# bao1x register map
Vendor: baochip; File version: 1.0
Registers are 32-bit, read-write, reset 0x0 unless marked. A register's access mark holds for its fields unless they carry their own. Offsets are from the block's base; [hi:lo] are bit positions; {n}, {i} and the like mark numbered series.

## IRQARRAY9
Base 0xE0017000
0x00 EV_SOFT — Software interrupt trigger register. ) Bits set to `1` will trigger an interrupt. Interrupts trigger on write, but the value will persist in the register, allowing software to determine if a software interrupt was triggered by reading back the register. Software is responsible for clearing the register to 0. Repeated `1` writes without clearing will still trigger an interrupt.
  [15:0] trigger
0x04 EV_EDGE_TRIGGERED — If a bit is set to 1, then the hardware trigger is edge-triggered
  [15:0] use_edge
0x08 EV_POLARITY — If a bit is set to 1, then the polarity is rising edge triggered; 0 is falling edge triggered. Bit is ignored if `edge_triggered` is 0.
  [15:0] rising
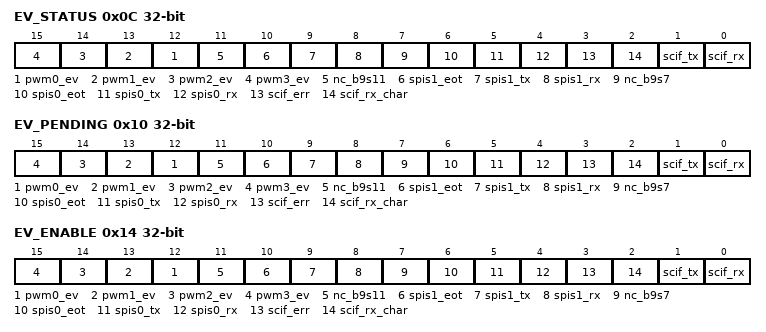
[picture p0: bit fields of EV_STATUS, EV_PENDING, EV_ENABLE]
0x0C EV_STATUS — `1` when a "pwm3_ev" event occurs. This event uses an `EventSourceFlex` form of triggering
  [n+12] pwm{n}_ev (n=0..3) — Level of the ``pwm{n}_ev`` event
  [11] nc_b9s11 — Level of the ``nc_b9s11`` event
  [10] spis1_eot — Level of the ``spis1_eot`` event
  [9] spis1_tx — Level of the ``spis1_tx`` event
  [8] spis1_rx — Level of the ``spis1_rx`` event
  [7] nc_b9s7 — Level of the ``nc_b9s7`` event
  [6] spis0_eot — Level of the ``spis0_eot`` event
  [5] spis0_tx — Level of the ``spis0_tx`` event
  [4] spis0_rx — Level of the ``spis0_rx`` event
  [3] scif_err — Level of the ``scif_err`` event
  [2] scif_rx_char — Level of the ``scif_rx_char`` event
  [1] scif_tx — Level of the ``scif_tx`` event
  [0] scif_rx — Level of the ``scif_rx`` event
0x10 EV_PENDING — `1` when a "pwm3_ev" event occurs. This event uses an `EventSourceFlex` form of triggering
  [n+12] pwm{n}_ev (n=0..3) — `1` when a "pwm{n}_ev" event occurs. This event uses an `EventSourceFlex` form of triggering
  [11] nc_b9s11 — `1` when a "nc_b9s11" event occurs. This event uses an `EventSourceFlex` form of triggering
  [10] spis1_eot — `1` when a "spis1_eot" event occurs. This event uses an `EventSourceFlex` form of triggering
  [9] spis1_tx — `1` when a "spis1_tx" event occurs. This event uses an `EventSourceFlex` form of triggering
  [8] spis1_rx — `1` when a "spis1_rx" event occurs. This event uses an `EventSourceFlex` form of triggering
  [7] nc_b9s7 — `1` when a "nc_b9s7" event occurs. This event uses an `EventSourceFlex` form of triggering
  [6] spis0_eot — `1` when a "spis0_eot" event occurs. This event uses an `EventSourceFlex` form of triggering
  [5] spis0_tx — `1` when a "spis0_tx" event occurs. This event uses an `EventSourceFlex` form of triggering
  [4] spis0_rx — `1` when a "spis0_rx" event occurs. This event uses an `EventSourceFlex` form of triggering
  [3] scif_err — `1` when a "scif_err" event occurs. This event uses an `EventSourceFlex` form of triggering
  [2] scif_rx_char — `1` when a "scif_rx_char" event occurs. This event uses an `EventSourceFlex` form of triggering
  [1] scif_tx — `1` when a "scif_tx" event occurs. This event uses an `EventSourceFlex` form of triggering
  [0] scif_rx — `1` when a "scif_rx" event occurs. This event uses an `EventSourceFlex` form of triggering
0x14 EV_ENABLE — `1` when a "pwm3_ev" event occurs. This event uses an `EventSourceFlex` form of triggering
  [n+12] pwm{n}_ev (n=0..3) — Write a ``1`` to enable the ``pwm{n}_ev`` Event
  [11] nc_b9s11 — Write a ``1`` to enable the ``nc_b9s11`` Event
  [10] spis1_eot — Write a ``1`` to enable the ``spis1_eot`` Event
  [9] spis1_tx — Write a ``1`` to enable the ``spis1_tx`` Event
  [8] spis1_rx — Write a ``1`` to enable the ``spis1_rx`` Event
  [7] nc_b9s7 — Write a ``1`` to enable the ``nc_b9s7`` Event
  [6] spis0_eot — Write a ``1`` to enable the ``spis0_eot`` Event
  [5] spis0_tx — Write a ``1`` to enable the ``spis0_tx`` Event
  [4] spis0_rx — Write a ``1`` to enable the ``spis0_rx`` Event
  [3] scif_err — Write a ``1`` to enable the ``scif_err`` Event
  [2] scif_rx_char — Write a ``1`` to enable the ``scif_rx_char`` Event
  [1] scif_tx — Write a ``1`` to enable the ``scif_tx`` Event
  [0] scif_rx — Write a ``1`` to enable the ``scif_rx`` Event
